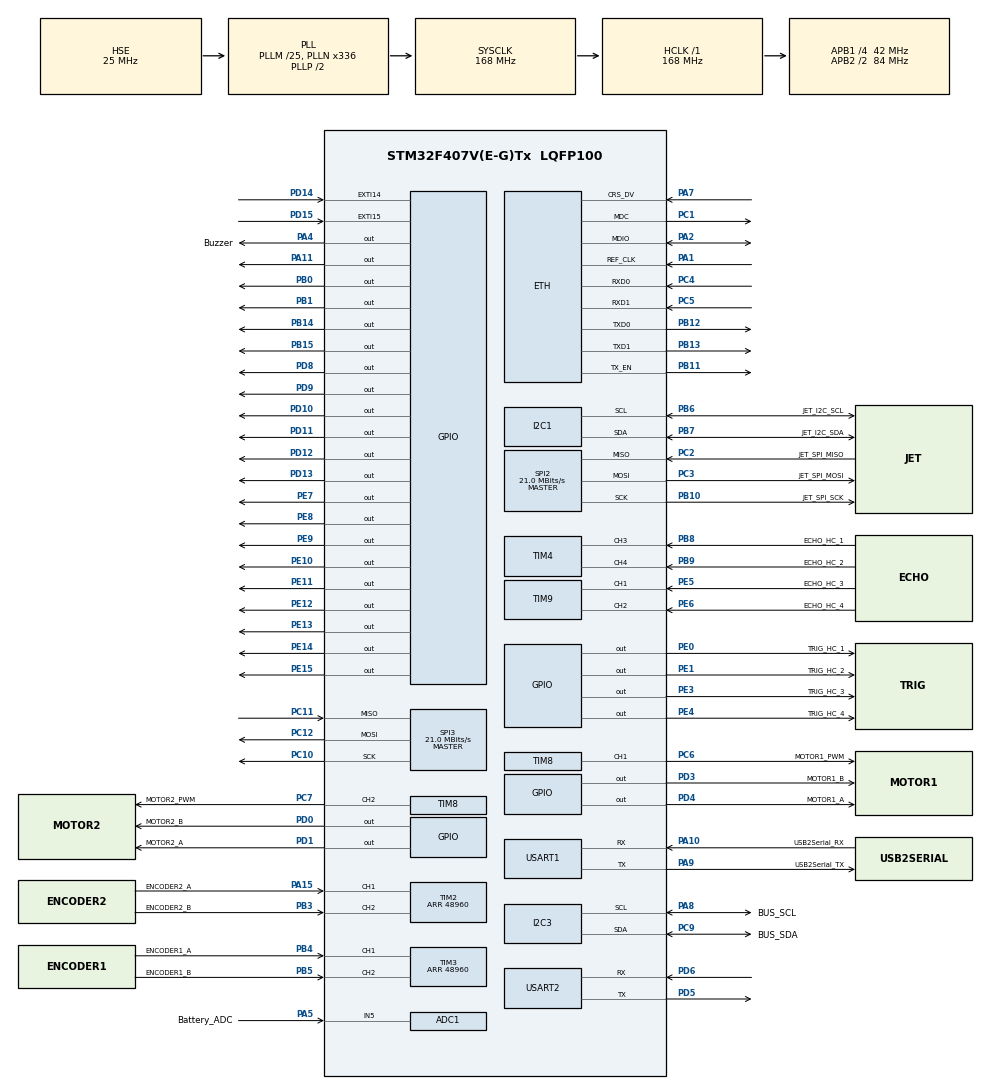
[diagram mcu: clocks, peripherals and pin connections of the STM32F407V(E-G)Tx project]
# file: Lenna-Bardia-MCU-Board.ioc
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ADC1.Channel-0\#ChannelRegularConversion=ADC_CHANNEL_5
ADC1.NbrOfConversionFlag=1
ADC1.Rank-0\#ChannelRegularConversion=1
ADC1.SamplingTime-0\#ChannelRegularConversion=ADC_SAMPLETIME_3CYCLES
ADC1.master=1
ETH.MediaInterface=HAL_ETH_RMII_MODE
Mcu.Family=STM32F4
Mcu.Name=STM32F407V(E-G)Tx
Mcu.Package=LQFP100
NVIC.PriorityGroup=NVIC_PRIORITYGROUP_4
NVIC.TIM4_IRQn=true\:0\:0\:false\:false\:true\:true\:true\:true
NVIC.TIM5_IRQn=true\:0\:0\:false\:false\:true\:true\:true\:true
NVIC.USART1_IRQn=true\:0\:0\:false\:false\:true\:true\:true\:true
PA1.Mode=RMII
PA1.Signal=ETH_REF_CLK
PA10.GPIO_Label=USB2Serial_RX
PA10.Mode=Asynchronous
PA10.Signal=USART1_RX
PA11.Signal=GPIO_Output
PA13.Mode=Serial_Wire
PA13.Signal=SYS_JTMS-SWDIO
PA14.Mode=Serial_Wire
PA14.Signal=SYS_JTCK-SWCLK
PA15.GPIO_Label=ENCODER2_A
PA15.Signal=S_TIM2_CH1_ETR
PA2.Mode=RMII
PA2.Signal=ETH_MDIO
PA4.GPIO_Label=Buzzer
PA4.Signal=GPIO_Output
PA5.GPIO_Label=Battery_ADC
PA5.Signal=ADCx_IN5
PA7.Mode=RMII
PA7.Signal=ETH_CRS_DV
PA8.GPIO_Label=BUS_SCL
PA8.Mode=I2C
PA8.Signal=I2C3_SCL
PA9.GPIO_Label=USB2Serial_TX
PA9.Mode=Asynchronous
PA9.Signal=USART1_TX
PB0.Signal=GPIO_Output
PB1.Signal=GPIO_Output
PB10.GPIO_Label=JET_SPI_SCK
PB10.Mode=Full_Duplex_Master
PB10.Signal=SPI2_SCK
PB11.Mode=RMII
PB11.Signal=ETH_TX_EN
PB12.Mode=RMII
PB12.Signal=ETH_TXD0
PB13.Mode=RMII
PB13.Signal=ETH_TXD1
PB14.Signal=GPIO_Output
PB15.Signal=GPIO_Output
PB3.GPIO_Label=ENCODER2_B
PB3.Signal=S_TIM2_CH2
PB4.GPIO_Label=ENCODER1_A
PB4.Signal=S_TIM3_CH1
PB5.GPIO_Label=ENCODER1_B
PB5.Signal=S_TIM3_CH2
PB6.GPIO_Label=JET_I2C_SCL
PB6.Mode=I2C
PB6.Signal=I2C1_SCL
PB7.GPIO_Label=JET_I2C_SDA
PB7.Mode=I2C
PB7.Signal=I2C1_SDA
PB8.GPIO_Label=ECHO_HC_1
PB8.Signal=S_TIM4_CH3
PB9.GPIO_Label=ECHO_HC_2
PB9.Signal=S_TIM4_CH4
PC1.Mode=RMII
PC1.Signal=ETH_MDC
PC10.Mode=Full_Duplex_Master
PC10.Signal=SPI3_SCK
PC11.Mode=Full_Duplex_Master
PC11.Signal=SPI3_MISO
PC12.Mode=Full_Duplex_Master
PC12.Signal=SPI3_MOSI
PC2.GPIO_Label=JET_SPI_MISO
PC2.Mode=Full_Duplex_Master
PC2.Signal=SPI2_MISO
PC3.GPIO_Label=JET_SPI_MOSI
PC3.Mode=Full_Duplex_Master
PC3.Signal=SPI2_MOSI
PC4.Mode=RMII
PC4.Signal=ETH_RXD0
PC5.Mode=RMII
PC5.Signal=ETH_RXD1
PC6.GPIO_Label=MOTOR1_PWM
PC6.Signal=S_TIM8_CH1
PC7.GPIO_Label=MOTOR2_PWM
PC7.Signal=S_TIM8_CH2
PC9.GPIO_Label=BUS_SDA
PC9.Mode=I2C
PC9.Signal=I2C3_SDA
PD0.GPIO_Label=MOTOR2_B
PD0.Signal=GPIO_Output
PD1.GPIO_Label=MOTOR2_A
PD1.Signal=GPIO_Output
PD10.Signal=GPIO_Output
PD11.Signal=GPIO_Output
PD12.Signal=GPIO_Output
PD13.Signal=GPIO_Output
PD14.Signal=GPXTI14
PD15.Signal=GPXTI15
PD3.GPIO_Label=MOTOR1_B
PD3.Signal=GPIO_Output
PD4.GPIO_Label=MOTOR1_A
PD4.Signal=GPIO_Output
PD5.Mode=Asynchronous
PD5.Signal=USART2_TX
PD6.Mode=Asynchronous
PD6.Signal=USART2_RX
PD8.Signal=GPIO_Output
PD9.Signal=GPIO_Output
PE0.GPIO_Label=TRIG_HC_1
PE0.Signal=GPIO_Output
PE1.GPIO_Label=TRIG_HC_2
PE1.Signal=GPIO_Output
PE10.Signal=GPIO_Output
PE11.Signal=GPIO_Output
PE12.Signal=GPIO_Output
PE13.Signal=GPIO_Output
PE14.Signal=GPIO_Output
PE15.Signal=GPIO_Output
PE3.GPIO_Label=TRIG_HC_3
PE3.Signal=GPIO_Output
PE4.GPIO_Label=TRIG_HC_4
PE4.Signal=GPIO_Output
PE5.GPIO_Label=ECHO_HC_3
PE5.Signal=S_TIM9_CH1
PE6.GPIO_Label=ECHO_HC_4
PE6.Signal=S_TIM9_CH2
PE7.Signal=GPIO_Output
PE8.Signal=GPIO_Output
PE9.Signal=GPIO_Output
PH0-OSC_IN.Mode=HSE-External-Oscillator
PH0-OSC_IN.Signal=RCC_OSC_IN
PH1-OSC_OUT.Mode=HSE-External-Oscillator
PH1-OSC_OUT.Signal=RCC_OSC_OUT
ProjectManager.HeapSize=0x200
ProjectManager.StackSize=0x400
ProjectManager.TargetToolchain=STM32CubeIDE
RCC.48MHZClocksFreq_Value=84000000
RCC.AHBFreq_Value=168000000
RCC.APB1CLKDivider=RCC_HCLK_DIV4
RCC.APB1Freq_Value=42000000
RCC.APB1TimFreq_Value=84000000
RCC.APB2CLKDivider=RCC_HCLK_DIV2
RCC.APB2Freq_Value=84000000
RCC.APB2TimFreq_Value=168000000
RCC.CortexFreq_Value=168000000
RCC.HCLKFreq_Value=168000000
RCC.HSE_VALUE=25000000
RCC.HSI_VALUE=16000000
RCC.LSE_VALUE=32768
RCC.PLLM=25
RCC.PLLN=336
RCC.PLLSourceVirtual=RCC_PLLSOURCE_HSE
RCC.SYSCLKFreq_VALUE=168000000
RCC.SYSCLKSource=RCC_SYSCLKSOURCE_PLLCLK
RCC.VCOOutputFreq_Value=336000000
SH.ADCx_IN5.0=ADC1_IN5,IN5
SH.S_TIM2_CH1_ETR.0=TIM2_CH1,Encoder_Interface
SH.S_TIM2_CH2.0=TIM2_CH2,Encoder_Interface
SH.S_TIM3_CH1.0=TIM3_CH1,Encoder_Interface
SH.S_TIM3_CH2.0=TIM3_CH2,Encoder_Interface
SH.S_TIM4_CH3.0=TIM4_CH3,Input_Capture3_from_TI3
SH.S_TIM4_CH4.0=TIM4_CH4,Input_Capture4_from_TI4
SH.S_TIM8_CH1.0=TIM8_CH1,PWM Generation1 CH1
SH.S_TIM8_CH2.0=TIM8_CH2,PWM Generation2 CH2
SH.S_TIM9_CH1.0=TIM9_CH1,Input_Capture1_from_TI1
SH.S_TIM9_CH2.0=TIM9_CH2,Input_Capture2_from_TI2
SPI2.BaudRatePrescaler=SPI_BAUDRATEPRESCALER_2
SPI2.CalculateBaudRate=21.0 MBits/s
SPI2.Direction=SPI_DIRECTION_2LINES
SPI2.Mode=SPI_MODE_MASTER
SPI2.VirtualType=VM_MASTER
SPI3.BaudRatePrescaler=SPI_BAUDRATEPRESCALER_2
SPI3.CalculateBaudRate=21.0 MBits/s
SPI3.Direction=SPI_DIRECTION_2LINES
SPI3.Mode=SPI_MODE_MASTER
SPI3.VirtualType=VM_MASTER
TIM1.Prescaler=168-1
TIM2.AutoReloadPreload=TIM_AUTORELOAD_PRELOAD_ENABLE
TIM2.EncoderMode=TIM_ENCODERMODE_TI12
TIM2.IC1Filter=10
TIM2.IC1Polarity=TIM_ICPOLARITY_FALLING
TIM2.IC2Filter=10
TIM2.Period=48960
TIM3.AutoReloadPreload=TIM_AUTORELOAD_PRELOAD_ENABLE
TIM3.EncoderMode=TIM_ENCODERMODE_TI12
TIM3.IC1Filter=10
TIM3.IC2Filter=10
TIM3.Period=48960
TIM4.Channel-Input_Capture3_from_TI3=TIM_CHANNEL_3
TIM4.Channel-Input_Capture4_from_TI4=TIM_CHANNEL_4
TIM5.Period=83
TIM5.Prescaler=10000
TIM8.AutoReloadPreload=TIM_AUTORELOAD_PRELOAD_ENABLE
TIM8.Channel-PWM\ Generation1\ CH1=TIM_CHANNEL_1
TIM8.Channel-PWM\ Generation2\ CH2=TIM_CHANNEL_2
TIM8.Period=1000
TIM8.Prescaler=8-1
TIM9.Channel-Input_Capture1_from_TI1=TIM_CHANNEL_1
TIM9.Channel-Input_Capture2_from_TI2=TIM_CHANNEL_2
USART1.VirtualMode=VM_ASYNC
USART2.VirtualMode=VM_ASYNC
VP_TIM1_VS_ClockSourceINT.Mode=Internal
VP_TIM4_VS_ClockSourceINT.Mode=Internal
VP_TIM5_VS_ClockSourceINT.Mode=Internal
VP_TIM8_VS_ClockSourceINT.Mode=Internal
board=custom

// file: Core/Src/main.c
/* USER CODE BEGIN Header */
/**
  ******************************************************************************
  * @file           : main.c
  * @brief          : Main program body
  ******************************************************************************
  * @attention
  *
  * Copyright (c) 2023 STMicroelectronics.
  * All rights reserved.
  *
  * This software is licensed under terms that can be found in the LICENSE file
  * in the root directory of this software component.
  * If no LICENSE file comes with this software, it is provided AS-IS.
  *
  ******************************************************************************
  */
/* USER CODE END Header */
#include "main.h"
#include "adc.h"
#include "eth.h"
#include "i2c.h"
#include "spi.h"
#include "tim.h"
#include "usart.h"
#include "gpio.h"

/* USER CODE BEGIN Includes */
#include "stdio.h"
#include "stdlib.h"
#include "stdbool.h"
#include "mcu_layout.h"
#include "ultrasonic.h"
#include "utilities.h"
#include "motion.h"
#include "pid.h"
#include "imu.h"
//#include "mpu6050.h"

/* USER CODE END Includes */

/* USER CODE BEGIN PM */
#define PUTCHAR_PROTOTYPE int __io_putchar(int ch)

/* USER CODE END PM */

/* USER CODE BEGIN PV */
uint8_t MSG[64];

uint8_t input_speed ;// step given by MATLAB code
uint16_t left_enc_temp = 0, right_enc_temp = 0 , right_enc_diff = 0, left_enc_diff = 0;
uint16_t encoder_tick[2] = {0};
float angular_speed_left,angular_speed_right;
uint16_t tst;

uint8_t flag_tx = 0, pid_tim_flag = 0, dir_flag = 0;

// ####################   Motor struct Value Setting   ###################
const motor_cfgType motor_right =
{
	MOTOR_PORT,
	MOTOR1_A_PIN,
	MOTOR_PORT,
	MOTOR1_B_PIN,
	&htim8,
	TIM_CHANNEL_1,
	1000,
	//1
};
const motor_cfgType motor_left =
{
	MOTOR_PORT,
	MOTOR2_A_PIN,
	MOTOR_PORT,
	MOTOR2_B_PIN,
	&htim8,
	TIM_CHANNEL_2,
	1000,
	//-1
};

// ####################   Ultra-Sonic struct Value Setting   ###################

const diffDrive_cfgType diff_robot =
{
	motor_right,
	motor_left,
	65,
	200
};

const ultrasonic_cfgType us_front =
{
	US1_TRIG_PORT,
	US1_TRIG_PIN,
	&htim4,
	TIM4,
	TIM_CHANNEL_3,
	168,
	1
};

// ####################   PID struct Value Setting   ###################

// definitions concerning PID gain values are made in the main.h header file
pid_cfgType pid_motor_left =
{
	Proportional_Gain_LEFT_MOTOR,
	Integral_Gain_LEFT_MOTOR,
	Derivative_Gain_LEFT_MOTOR,
	Sampling_Time,
	Lower_Saturation_Limit,
	Upper_Saturation_Limit,
	0,
	0,
	0,
	0,
	0,
	1,
	0,
	0
};

pid_cfgType pid_motor_right =
{
	Proportional_Gain_RIGHT_MOTOR,
	Integral_Gain_RIGHT_MOTOR,
	Derivative_Gain_RIGHT_MOTOR,
	Sampling_Time,
	Lower_Saturation_Limit,
	Upper_Saturation_Limit,
	0,
	0,
	0,
	0,
	0,
	1,
	0,
	0
};

// ####################   IMU struct Value Setting   ###################

imu_cfgType gy80=
{
	&hi2c3,
	0,
	0,
	0
};
/* USER CODE END PV */

void SystemClock_Config(void);

/* USER CODE BEGIN 0 */

// ####################   UART Tx -> printf   ####################
PUTCHAR_PROTOTYPE
{
  /* Place your implementation of fputc here */
  /* e.g. write a character to the USART1 and Loop until the end of transmission */
  HAL_UART_Transmit(&huart1, (uint8_t *)&ch, 1, 0xFFFF);

  return ch;
}

/* USER CODE END 0 */

int main(void)
{

  /* MCU Configuration--------------------------------------------------------*/

  /* Reset of all peripherals, Initializes the Flash interface and the Systick. */
  HAL_Init();

  /* Configure the system clock */
  SystemClock_Config();

  /* Initialize all configured peripherals */
  MX_GPIO_Init();
  MX_ADC1_Init();
  MX_ETH_Init();
  MX_I2C1_Init();
  MX_I2C3_Init();
  MX_SPI2_Init();
  MX_SPI3_Init();
  MX_TIM2_Init();
  MX_TIM3_Init();
  MX_TIM4_Init();
  MX_TIM8_Init();
  MX_TIM9_Init();
  MX_USART1_UART_Init();
  MX_USART2_UART_Init();
  MX_TIM1_Init();
  MX_TIM5_Init();
  /* USER CODE BEGIN 2 */
  LRL_Delay_Init();			// TIMER Initialization for Delay us
  LRL_US_Init(us_front); 	// TIMER Initialization for Ultrasonics

  HAL_TIM_PWM_Start(&htim8, TIM_CHANNEL_1);
  HAL_TIM_PWM_Start(&htim8, TIM_CHANNEL_2);
  HAL_TIM_Encoder_Start(&htim3, TIM_CHANNEL_ALL);
  HAL_TIM_Encoder_Start(&htim2, TIM_CHANNEL_ALL);
//  HAL_TIM_Base_Init(&htim5);
  HAL_TIM_Base_Start_IT(&htim5);
  HAL_I2C_Init(&hi2c3);

  //printf("Lenna Robotics Research Lab. \r\n");
  // HAL_Delay(1000);

// ####################   Encoder Initialization   ####################
  TIM2->CNT = 0;
  TIM3->CNT = 0;
  encoder_tick[0] = (TIM2->CNT);
  encoder_tick[1] = (TIM3->CNT);

// ####################   MATLAB Communication Initialization   ####################

 /*
  // Initializing the MATLAB communication and identification
  // Receiving info from MATLAB SIMULINK for system identification and commands to run speed
  HAL_UART_Receive_IT(&huart1,&input_speed, 1); // getting the speed

 */

  LRL_PID_Init(&pid_motor_left,  1);
  LRL_PID_Init(&pid_motor_right, 1);
  LRL_MPU_Init(&gy80);

  //uint8_t tstt[3];
  /* USER CODE END 2 */

  /* Infinite loop */
  /* USER CODE BEGIN WHILE */
  while (1)
  {
// ####################   imu setup  ####################
//	  LRL_ACCEL_Read(&gy80);
	  uint8_t data[6];
	  int16_t mytst[3];

//	  MPU6050_Read_All(&hi2c3, &gy80);
	  LRL_Read_Gyro(&gy80);
	  LRL_Read_Accel(&gy80);

	  static uint32_t prev_time = 0;
	  uint32_t curr_time = HAL_GetTick();
	  float dt = (curr_time - prev_time) / 1000.0f;
	  prev_time = curr_time;

	  complementary_filter(&gy80);
//	  HAL_I2C_Mem_Read(&hi2c3, 0xD0, 0x75, 1, &data[0], 1,10);
//	  HAL_I2C_Mem_Read(&hi2c3, GYRO_ADDR_R, 0x29, 1, &data[1], 1,10);
//	  mytst[0] = ((data[1]<<8)|data[0]);
//	  mytst[1] = ((data[3]<<8)|data[2]);
//	  mytst[2] = ((data[5]<<8)|data[4]);

//	  HAL_I2C_Mem_Read(&hi2c3,0xD3,0x0F,1,&myimu,1,100);
//	  LRL_GY80_Init(&hi2c3,tstt);

	  sprintf(MSG,"the speed is : %3.2f\t %3.2f\t %3.2f\n\r",gy80.roll,gy80.pitch,gy80.yaw);
//	  sprintf(MSG,"the speed is : %d\n\r", data[0]);
	  HAL_UART_Transmit(&huart1,MSG, 64,100);
//	  HAL_Delay(1);

// ####################   Motor Test Scenarios   ####################
//	  LRL_Motion_Control(diff_robot, -100, 100);
//	  if(input_speed >= 50 && input_speed <= 100)
//	  {
//		  LRL_Motor_Speed(motor_left, -1*input_speed);
//	  }
//	  else
//	  {
//		  HAL_GPIO_TogglePin(BLINK_LED_PORT, BLINK_LED_PIN);
//		  HAL_Delay(100);
//		  LRL_Motor_Speed(motor_left, 0);
//	  }

//	  LRL_Motor_Speed(motor_right, input_speed);

// ####################   Encoder Reading   ####################
/*
	  if(pid_tim_flag == 1)
	  {
		  encoder_tick[0] = (TIM2->CNT); // Left Motor Encoder
		  encoder_tick[1] = (TIM3->CNT); // Right Motor Encoder

		  // Reading the Encoder for the right Motor
//		  if(__HAL_TIM_IS_TIM_COUNTING_DOWN(&htim3))
//		  {
//			  if(encoder_tick[1] - right_enc_temp >= 0)
//			  {
////				  right_enc_diff = encoder_tick[1] - right_enc_temp;
//				  right_enc_diff = (48960 + encoder_tick[1]) - right_enc_temp;
//			  }
//			  else
//			  {
////				  right_enc_diff = (48960 - right_enc_temp) + encoder_tick[1];
//				  right_enc_diff = -(encoder_tick[1] - right_enc_temp);
//			  }
//			  right_enc_temp = encoder_tick[1];

//		  }
////		  else
//		  {

		  ;
		  if(__HAL_TIM_IS_TIM_COUNTING_DOWN(&htim3) == 0)
		  {
			  if(encoder_tick[1] - right_enc_temp >= 0)
			  {
				  right_enc_diff = encoder_tick[1] - right_enc_temp;
			  }
			  else
			  {
				  right_enc_diff = (48960 - right_enc_temp) + encoder_tick[1];
			  }
			  right_enc_temp = encoder_tick[1];
		  }
		  else
		  {
			  if(right_enc_temp - encoder_tick[1] >= 0)
			  {
				  right_enc_diff = -(encoder_tick[1] - right_enc_temp);
			  }
			  else
			  {
				  right_enc_diff = (48960 - encoder_tick[1]) + right_enc_temp;
			  }
			  right_enc_temp = encoder_tick[1];
		  }
//		  }

			  // Reading the Encoder for the left Motor

		  if(__HAL_TIM_IS_TIM_COUNTING_DOWN(&htim2) == 0)
		  {
			  if(encoder_tick[0] - left_enc_temp >= 0)
			  {
				  left_enc_diff = encoder_tick[0] - left_enc_temp;
			  }
			  else
			  {
				  left_enc_diff = (48960 - left_enc_temp) + encoder_tick[0];
			  }
			  left_enc_temp = encoder_tick[0];
		  }
		  else
		  {
			  if(left_enc_temp - encoder_tick[0] >= 0)
			  {
				  left_enc_diff = -(encoder_tick[0] - left_enc_temp);
			  }
			  else
			  {
				  left_enc_diff = (48960 - encoder_tick[0]) + left_enc_temp;
			  }
			  left_enc_temp = encoder_tick[0];
		  }

*/
// ####################   PID control   ####################

/*

// The transmission of the encoder tick to angular velocity is (6000 / 48960)

		  angular_speed_left = left_enc_diff * Tick2RMP_Rate ;//  *Speed2PWM_Rate;
		  angular_speed_right = right_enc_diff * Tick2RMP_Rate // * Speed2PWM_Rate;

		  LRL_PID_Update(&pid_motor_left,angular_speed_left,120);
//		  LRL_Motor_Speed(motor_left, pid_motor_left.Control_Signal);

		  LRL_PID_Update(&pid_motor_right,angular_speed_right,120);
//		  LRL_Motor_Speed(motor_right, pid_motor_right.Control_Signal);
		  pid_tim_flag = 0;
//		  HAL_GPIO_WritePin(BLINK_LED_PORT, BLINK_LED_PIN, 1);
		  LRL_Motor_Speed(motor_left, pid_motor_left.Control_Signal);
		  LRL_Motor_Speed(motor_right, pid_motor_right.Control_Signal);
		  sprintf(MSG,"the speed is : %5.1f\t%d\t%5.1f\t%5.1f\r\n ",angular_speed_left,pid_motor_left.Control_Signal,pid_motor_left.Prev_Error,pid_motor_left.Integrator_Amount);
		  HAL_UART_Transmit_IT(&huart1,MSG, 64);
	  }
*/

// ####################   Transmit Speed for MATLAB Identification   ####################
	  /*
	  // Sending the speed that has been read from encoder only if there is a receiving data
	  if(flag_tx == 1){
		  HAL_UART_Transmit(&huart1,(uint8_t *)&right_enc_diff, sizeof(right_enc_diff),10);
		  flag_tx = 0;
	  }

	  // Pay great attention to the delayed time hence the wrong data can be received in MATLAB
	  // Since the Data is read roughly every 0.01 second this amount of delay is necessary for correct transmission
	  HAL_Delay(10);

	  */

//	  sprintf(MSG, "encoder ticks: %04d\t%04d\r\n", encoder_tick[0], encoder_tick[1]);
//	  printf(MSG);

//	LRL_US_Trig(us_front);	// Trigging the Sensor for 15us
//
//	sprintf(MSG, "Distance:\t %05.1f \r\n", LRL_US_Read(us_front));
//	printf(MSG);
//
	  //HAL_Delay(1000);

//	  	sprintf(MSG, "Distance:\t %d \r\n", i);
//	  	printf(i);

    /* USER CODE END WHILE */

  }
}

void SystemClock_Config(void)
{
  RCC_OscInitTypeDef RCC_OscInitStruct = {0};
  RCC_ClkInitTypeDef RCC_ClkInitStruct = {0};

  /** Configure the main internal regulator output voltage
  */
  __HAL_RCC_PWR_CLK_ENABLE();
  __HAL_PWR_VOLTAGESCALING_CONFIG(PWR_REGULATOR_VOLTAGE_SCALE1);

  /** Initializes the RCC Oscillators according to the specified parameters
  * in the RCC_OscInitTypeDef structure.
  */
  RCC_OscInitStruct.OscillatorType = RCC_OSCILLATORTYPE_HSE;
  RCC_OscInitStruct.HSEState = RCC_HSE_ON;
  RCC_OscInitStruct.PLL.PLLState = RCC_PLL_ON;
  RCC_OscInitStruct.PLL.PLLSource = RCC_PLLSOURCE_HSE;
  RCC_OscInitStruct.PLL.PLLM = 25;
  RCC_OscInitStruct.PLL.PLLN = 336;
  RCC_OscInitStruct.PLL.PLLP = RCC_PLLP_DIV2;
  RCC_OscInitStruct.PLL.PLLQ = 4;
  if (HAL_RCC_OscConfig(&RCC_OscInitStruct) != HAL_OK)
  {
    Error_Handler();
  }

  /** Initializes the CPU, AHB and APB buses clocks
  */
  RCC_ClkInitStruct.ClockType = RCC_CLOCKTYPE_HCLK|RCC_CLOCKTYPE_SYSCLK
                              |RCC_CLOCKTYPE_PCLK1|RCC_CLOCKTYPE_PCLK2;
  RCC_ClkInitStruct.SYSCLKSource = RCC_SYSCLKSOURCE_PLLCLK;
  RCC_ClkInitStruct.AHBCLKDivider = RCC_SYSCLK_DIV1;
  RCC_ClkInitStruct.APB1CLKDivider = RCC_HCLK_DIV4;
  RCC_ClkInitStruct.APB2CLKDivider = RCC_HCLK_DIV2;

  if (HAL_RCC_ClockConfig(&RCC_ClkInitStruct, FLASH_LATENCY_5) != HAL_OK)
  {
    Error_Handler();
  }
}

/* USER CODE BEGIN 4 */

// ####################   Ultra Sonic Callback   ####################

void HAL_TIM_IC_CaptureCallback(TIM_HandleTypeDef *htim)
{
	// TIMER Input Capture Callback
	LRL_US_TMR_IC_ISR(htim, us_front);
}

// ####################   UART Receive Callback   ####################

void HAL_UART_RxCpltCallback(UART_HandleTypeDef *huart){
	HAL_UART_Receive_IT(&huart1,&input_speed, 1);
	flag_tx = 1;
}

// ####################   Timer To Creat 0.01 Delay Callback   ####################

void HAL_TIM_PeriodElapsedCallback(TIM_HandleTypeDef* htim){
	if(htim == &htim5)
	{
		pid_tim_flag = 1;
	}

}

// ####################   I2C Callback   ####################

void HAL_I2C_MemRxCpltCallback(I2C_HandleTypeDef *hi2c){
if(hi2c == &hi2c3)
	{
////		LRL_IMU_Read(&gy80);
		HAL_GPIO_WritePin(BLINK_LED_PORT, BLINK_LED_PIN, 1);
//	LRL_GYRO_Read(&gy80);
	}
}
//void HAL_UART_TxCpltCallback(UART_HandleTypeDef *huart){
//	//
//}

//void HAL_TIM_PeriodElapsedCallback(TIM_HandleTypeDef* htim)
//{
//	// TIMER Overflow Callback
//	LRL_US_TMR_OVF_ISR(htim, us_front);
//}

/* USER CODE END 4 */

void Error_Handler(void)
{
  __disable_irq();
  while (1)
  {
  }
}
